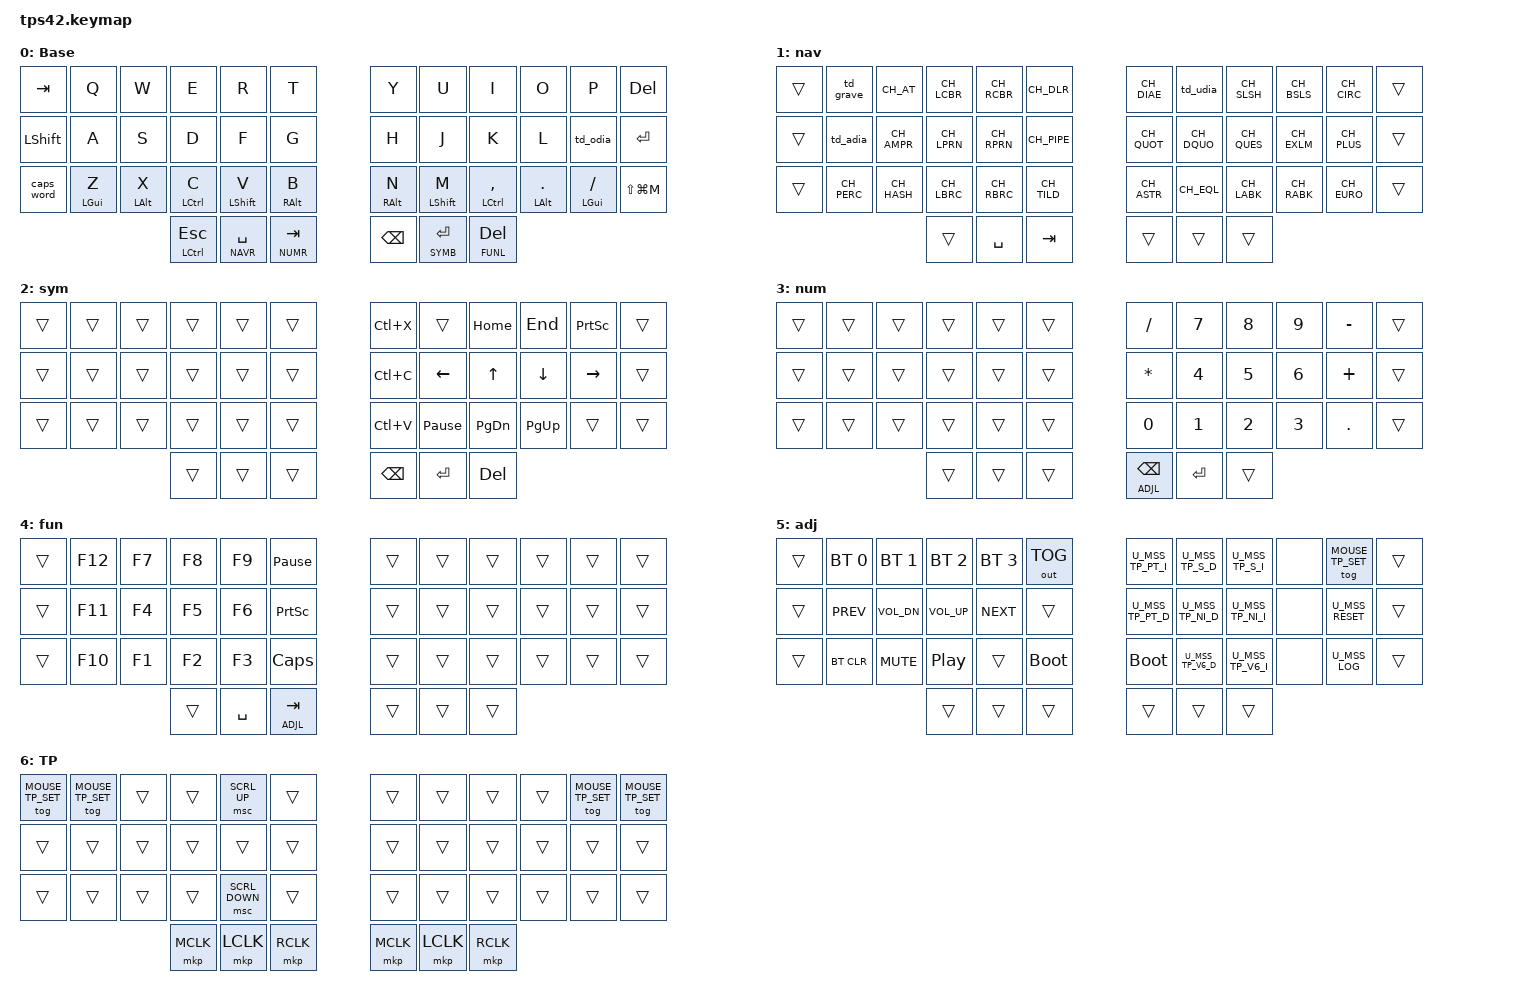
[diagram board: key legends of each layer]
/*
 * Copyright (c) 2020 The ZMK Contributors
 *
 * SPDX-License-Identifier: MIT
 */

#include <behaviors.dtsi>
#include <dt-bindings/zmk/keys.h>
#include <dt-bindings/zmk/ext_power.h>
#include <dt-bindings/zmk/outputs.h>
#include <dt-bindings/zmk/bt.h>

#include "include/swiss-keymap.h"

#define BASE           0
#define NAVR           1
#define SYMB           2
#define NUMR           3
#define FUNL           4
#define ADJL           5    
#define MOUSE_TP_SET   6
#define MOUSE_TP       7



/*
 * Defines to enable/disable features
 *
 * These defines allow us to conditionally enable and disable parts of the keymap config.
 *
 * For example, if we decide to build the firmware without the mouse features, we can
 * disable all the config options that rely on those forks and modules without having
 * to edit the entire keymap file manually every time.
 */
#define HAS_MOUSE_TP

#ifdef HAS_MOUSE_KEYS
  #include <dt-bindings/zmk/mouse.h>
  #include <behaviors/mouse_keys.dtsi>
#endif  // HAS_MOUSE_KEYS

#ifdef HAS_MOUSE_TP
  // We store the trackpoint settings in a separate file
  // to make organization a little easier.
  #include "include/mouse_tp.dtsi"
#endif  // HAS_MOUSE_TP



// Adjust layer keys based on enabled features.
//
// This prevents build errors when we build the firmware
// without the mouse keys PR or the TP module.

#ifdef HAS_MOUSE_TP
  #define U_TOG_TP_SET &tog MOUSE_TP_SET
#else
  #define U_TOG_TP_SET &none
#endif  // HAS_MOUSE_TP

// Disable line-wrap in your editor to see a "visualization" of the key layouts
/ {
    macros {
        md_code_i: md_code_i {
            label = "MD Code Inline";
            compatible = "zmk,behavior-macro";
            #binding-cells = <0>;
            bindings
                = <&macro_tap_time 50>
                , <&macro_tap &kp CH_GRV>
                , <&macro_tap_time 10>
                , <&macro_tap &kp CH_GRV &kp LEFT>
                ;
        };
        md_code_b: md_code_b {
            label = "MD Code Block";
            compatible = "zmk,behavior-macro";
            #binding-cells = <0>;
            bindings
                = <&macro_tap_time 10>
                , <&macro_tap &kp CH_GRV &kp CH_GRV &kp CH_GRV &kp CH_GRV &kp CH_GRV &kp CH_GRV &kp LEFT &kp LEFT &kp LEFT &kp RET &kp RET &kp UP>
                ;
        };
        up_ch_adia: up_ch_adia {
            label = "Uppercase CH_ADIA";
            compatible = "zmk,behavior-macro";
            #binding-cells = <0>;
            bindings
                = <&macro_tap_time 10>
                , <&macro_tap &kp CLCK &kp CH_ADIA &kp CLCK>
                ;
        };
        up_ch_udia: up_ch_udia {
            label = "Uppercase CH_UDIA";
            compatible = "zmk,behavior-macro";
            #binding-cells = <0>;
            bindings
                = <&macro_tap_time 10>
                , <&macro_tap &kp CLCK &kp CH_UDIA &kp CLCK>
                ;
        };
        
        up_ch_odia: up_ch_odia {
            label = "Uppercase CH_ODIA";
            compatible = "zmk,behavior-macro";
            #binding-cells = <0>;
            bindings
                = <&macro_tap_time 10>
                , <&macro_tap &kp CLCK &kp CH_ODIA &kp CLCK>
                ;
        };
    };
	behaviors {
        hm: homerow_mods {
            compatible = "zmk,behavior-hold-tap";
            label = "HOMEROW_MODS";
            #binding-cells = <2>;
            tapping-term-ms = <180>;
            quick_tap_ms = <0>;
            flavor = "tap-preferred";
            bindings = <&kp>, <&kp>;
        };
         td_udia: tap_dance_udia {
            compatible = "zmk,behavior-tap-dance";
            label = "TAP_DANCE_UDIA";
            #binding-cells = <0>;
            tapping-term-ms = <200>;
            bindings = <&kp CH_UDIA>, <&up_ch_udia>;
        };
         td_adia: tap_dance_adia {
            compatible = "zmk,behavior-tap-dance";
            label = "TAP_DANCE_ADIA";
            #binding-cells = <0>;
            tapping-term-ms = <200>;
            bindings = <&kp CH_ADIA>, <&up_ch_adia>;
        };
         td_odia: tap_dance_odia {
            compatible = "zmk,behavior-tap-dance";
            label = "TAP_DANCE_ODIA";
            #binding-cells = <0>;
            tapping-term-ms = <200>;
            bindings = <&kp CH_ODIA>, <&up_ch_odia>;
        };
        td_grave: tap_dance_grave {
            compatible = "zmk,behavior-tap-dance";
            label = "TAP_DANCE_GRAVE";
            #binding-cells = <0>;
            tapping-term-ms = <300>;
            bindings = <&kp CH_GRV>, <&md_code_i>, <&md_code_b>;
        };
    };
// /*
//  *
//  *          ,-----------------------------.                                ,-----------------------------.
//  *          | 00 | 01 | 02 | 03 | 04 | 05 |                                | 06 | 07 | 08 | 09 | 10 | 11 |
//  *          ,----+----+----+----+----+----|                                |----+----+----+----+----+----.
//  *          | 12 | 13 | 14 | 15 | 16 | 17 |                                | 18 | 19 | 20 | 21 | 22 | 23 |
//  *          |----+----+----+----+----+----|                                |----+----+----+----+----+----|
//  *          | 24 | 25 | 26 | 27 | 28 | 29 |                                | 30 | 31 | 32 | 33 | 34 | 35 |
//  *          `-------------------+----+----+----.                      ,----+----+----+-------------------'
//  *                              | 36 | 37 | 38 |                      | 39 | 40 | 41 |
//  *                              `--------------'                      `--------------'
//  */

    combos {
        compatible = "zmk,combos";
        combo_caps_word {
            timeout-ms = <50>;
            key-positions = <28 31>;
            bindings = <&caps_word>;
        };
    };
    keymap {
    compatible = "zmk,keymap";

    Base_layer {
      display-name = "Base";
      bindings = <
// ╭────────────────────────┬────────────────────────┬────────────────────────┬────────────────────────┬────────────────────────┬────────────────────────╮    ╭────────────────────────┬────────────────────────┬────────────────────────┬───────────────────────┬────────────────────────┬────────────────────────╮
     &kp TAB                  &kp Q                    &kp W                    &kp E                    &kp R                    &kp T                         &kp Y                    &kp U                    &kp I                    &kp O                    &kp P                    &kp DEL
// ├────────────────────────┼────────────────────────┼────────────────────────┼────────────────────────┼────────────────────────┼────────────────────────┤    ├────────────────────────┼────────────────────────┼────────────────────────┼───────────────────────┼────────────────────────┼────────────────────────┤
     &kp LSHIFT               &kp A                    &kp S                    &kp D                    &kp F                    &kp G                         &kp H                    &kp J                    &kp K                    &kp L                    &td_odia                 &kp ENTER
// ├────────────────────────┼────────────────────────┼────────────────────────┼────────────────────────┼────────────────────────┼────────────────────────┤    ├────────────────────────┼────────────────────────┼────────────────────────┼───────────────────────┼────────────────────────┼────────────────────────┤
     &caps_word               &hm LGUI Z               &hm LALT X               &hm LCTRL C              &hm LSHFT V              &hm RALT B                    &hm RALT N               &hm LSHFT M              &hm LCTRL COMMA          &hm LALT DOT             &hm LGUI FSLH            &kp LS(LG(M))
// ╰────────────────────────┴────────────────────────┴────────────────────────┴────────────────────────┼────────────────────────┼────────────────────────┤    ├────────────────────────┼────────────────────────┼────────────────────────┼───────────────────────┼────────────────────────┼────────────────────────╯
                                                                                &mt LCTRL ESC            &lt NAVR SPACE           &lt NUMR TAB                  &kp BSPC                 &lt SYMB RET             &lt FUNL DEL 
//                                                                            ╰────────────────────────┴────────────────────────┴────────────────────────╯    ╰────────────────────────┴────────────────────────┴────────────────────────╯
      >;
    };


    Navigation_layer {
      display-name = "nav";
      bindings = <
// ╭────────────────────────┬────────────────────────┬────────────────────────┬────────────────────────┬────────────────────────┬────────────────────────╮    ╭────────────────────────┬────────────────────────┬────────────────────────┬────────────────────────┬────────────────────────┬────────────────────────╮
     &trans                   &td_grave                &kp CH_AT                &kp CH_LCBR              &kp CH_RCBR              &kp CH_DLR                    &kp CH_DIAE              &td_udia                 &kp CH_SLSH              &kp CH_BSLS              &kp CH_CIRC              &trans
// ├────────────────────────┼────────────────────────┼────────────────────────┼────────────────────────┼────────────────────────┼────────────────────────┤    ├────────────────────────┼────────────────────────┼────────────────────────┼────────────────────────┼────────────────────────┼────────────────────────┤
     &trans                   &td_adia                 &kp CH_AMPR              &kp CH_LPRN              &kp CH_RPRN              &kp CH_PIPE                   &kp CH_QUOT              &kp CH_DQUO              &kp CH_QUES              &kp CH_EXLM              &kp CH_PLUS              &trans
// ├────────────────────────┼────────────────────────┼────────────────────────┼────────────────────────┼────────────────────────┼────────────────────────┤    ├────────────────────────┼────────────────────────┼────────────────────────┼────────────────────────┼────────────────────────┼────────────────────────┤
     &trans                   &kp CH_PERC              &kp CH_HASH              &kp CH_LBRC              &kp CH_RBRC              &kp CH_TILD                   &kp CH_ASTR              &kp CH_EQL               &kp CH_LABK              &kp CH_RABK              &kp CH_EURO              &trans
// ╰────────────────────────┴────────────────────────┴────────────────────────┴────────────────────────┼────────────────────────┼────────────────────────┤    ├────────────────────────┼────────────────────────┼────────────────────────┼────────────────────────┴────────────────────────┼────────────────────────╯
                                                                                &trans                   &kp SPACE                &kp TAB                       &trans                   &trans                   &trans
//                                                                            ╰────────────────────────┴────────────────────────┴────────────────────────╯    ╰────────────────────────┴────────────────────────┴────────────────────────╯
      >;
    };


    Symbol_layer {
      display-name = "sym";
      bindings = <
// ╭────────────────────────┬────────────────────────┬────────────────────────┬────────────────────────┬────────────────────────┬────────────────────────╮    ╭────────────────────────┬────────────────────────┬────────────────────────┬────────────────────────┬────────────────────────┬────────────────────────╮
     &trans                   &trans                   &trans                   &trans                   &trans                   &trans                        &kp LC(X)                &trans                   &kp HOME                 &kp END                  &kp PSCRN                 &trans
// ├────────────────────────┼────────────────────────┼────────────────────────┼────────────────────────┼────────────────────────┼────────────────────────┤    ├────────────────────────┼────────────────────────┼────────────────────────┼────────────────────────┼────────────────────────┼────────────────────────┤
     &trans                   &trans                   &trans                   &trans                   &trans                   &trans                        &kp LC(C)                &kp LEFT                 &kp UP                   &kp DOWN                 &kp RIGHT                 &trans
// ├────────────────────────┼────────────────────────┼────────────────────────┼────────────────────────┼────────────────────────┼────────────────────────┤    ├────────────────────────┼────────────────────────┼────────────────────────┼────────────────────────┼────────────────────────┼────────────────────────┤
     &trans                   &trans                   &trans                   &trans                   &trans                   &trans                        &kp LC(V)                &kp PAUSE_BREAK          &kp PG_DN                &kp PG_UP                &trans                    &trans
// ╰────────────────────────┴────────────────────────┴────────────────────────┴────────────────────────┼────────────────────────┼────────────────────────┤    ├────────────────────────┼────────────────────────┼────────────────────────┼────────────────────────┴────────────────────────┼────────────────────────╯
                                                                                &trans                   &trans                   &trans                        &kp BSPC                 &kp RET                  &kp DEL
//                                                                            ╰────────────────────────┴────────────────────────┴────────────────────────╯    ╰────────────────────────┴────────────────────────┴────────────────────────╯
      >;
    };


    Number_layer {
      display-name = "num";
      bindings = <
// ╭────────────────────────┬────────────────────────┬────────────────────────┬────────────────────────┬────────────────────────┬────────────────────────╮    ╭────────────────────────┬────────────────────────┬────────────────────────┬────────────────────────┬────────────────────────┬────────────────────────╮
     &trans                   &trans                   &trans                   &trans                   &trans                   &trans                        &kp SLASH                &kp N7                   &kp N8                   &kp N9                   &kp MINUS                &trans
// ├────────────────────────┼────────────────────────┼────────────────────────┼────────────────────────┼────────────────────────┼────────────────────────┤    ├────────────────────────┼────────────────────────┼────────────────────────┼────────────────────────┼────────────────────────┼────────────────────────┤
     &trans                   &trans                   &trans                   &trans                   &trans                   &trans                        &kp ASTRK                &kp N4                   &kp N5                   &kp N6                   &kp PLUS                 &trans
// ├────────────────────────┼────────────────────────┼────────────────────────┼────────────────────────┼────────────────────────┼────────────────────────┤    ├────────────────────────┼────────────────────────┼────────────────────────┼────────────────────────┼────────────────────────┼────────────────────────┤
     &trans                   &trans                   &trans                   &trans                   &trans                   &trans                        &kp N0                   &kp N1                   &kp N2                   &kp N3                   &kp DOT                  &trans
// ╰────────────────────────┴────────────────────────┴────────────────────────┴────────────────────────┼────────────────────────┼────────────────────────┤    ├────────────────────────┼────────────────────────┼────────────────────────┼────────────────────────┴────────────────────────┼────────────────────────╯
                                                                                &trans                   &trans                   &trans                        &lt ADJL BSPC            &kp RET                  &trans
//                                                                            ╰────────────────────────┴────────────────────────┴────────────────────────╯    ╰────────────────────────┴────────────────────────┴────────────────────────╯
      >;
    };


    Function_layer {
      display-name = "fun";
      bindings = <
// ╭────────────────────────┬────────────────────────┬────────────────────────┬────────────────────────┬────────────────────────┬────────────────────────╮    ╭────────────────────────┬────────────────────────┬────────────────────────┬────────────────────────┬────────────────────────┬────────────────────────╮
     &trans                   &kp F12                  &kp F7                   &kp F8                   &kp F9                   &kp PAUSE_BREAK               &trans                   &trans                   &trans                   &trans                   &trans                   &trans
// ├────────────────────────┼────────────────────────┼────────────────────────┼────────────────────────┼────────────────────────┼────────────────────────┤    ├────────────────────────┼────────────────────────┼────────────────────────┼────────────────────────┼────────────────────────┼────────────────────────┤
     &trans                   &kp F11                  &kp F4                   &kp F5                   &kp F6                   &kp PSCRN                     &trans                   &trans                   &trans                   &trans                   &trans                   &trans
// ├────────────────────────┼────────────────────────┼────────────────────────┼────────────────────────┼────────────────────────┼────────────────────────┤    ├────────────────────────┼────────────────────────┼────────────────────────┼────────────────────────┼────────────────────────┼────────────────────────┤
     &trans                   &kp F10                  &kp F1                   &kp F2                   &kp F3                   &kp CLCK                      &trans                   &trans                   &trans                   &trans                   &trans                   &trans
// ╰────────────────────────┴────────────────────────┴────────────────────────┴────────────────────────┼────────────────────────┼────────────────────────┤    ├────────────────────────┼────────────────────────┼────────────────────────┼────────────────────────┴────────────────────────┼────────────────────────╯
                                                                                &trans                   &kp SPACE                &lt ADJL TAB                  &trans                   &trans                   &trans
//                                                                            ╰────────────────────────┴────────────────────────┴────────────────────────╯    ╰────────────────────────┴────────────────────────┴────────────────────────╯
      >;
    };

#ifndef HAS_MOUSE_TP

    Adjustment_layer {
      display-name = "adj";
      bindings = <
// ╭────────────────────────┬────────────────────────┬────────────────────────┬────────────────────────┬────────────────────────┬────────────────────────╮    ╭────────────────────────┬────────────────────────┬────────────────────────┬────────────────────────┬────────────────────────┬────────────────────────╮
     &trans                   &bt BT_SEL 0             &bt BT_SEL 1             &bt BT_SEL 2             &bt BT_SEL 3             &out OUT_TOG                  &trans                   &trans                   &trans                   &trans                   &trans                   &trans
// ├────────────────────────┼────────────────────────┼────────────────────────┼────────────────────────┼────────────────────────┼────────────────────────┤    ├────────────────────────┼────────────────────────┼────────────────────────┼────────────────────────┼────────────────────────┼────────────────────────┤
     &trans                   &kp C_PREV               &kp C_VOL_DN             &kp C_VOL_UP             &kp C_NEXT               &trans                        &trans                   &trans                   &trans                   &trans                   &trans                   &trans
// ├────────────────────────┼────────────────────────┼────────────────────────┼────────────────────────┼────────────────────────┼────────────────────────┤    ├────────────────────────┼────────────────────────┼────────────────────────┼────────────────────────┼────────────────────────┼────────────────────────┤
     &trans                   &bt BT_CLR               &kp K_MUTE               &kp C_PP                 &trans                   &bootloader                   &bootloader              &trans                   &trans                   &trans                   &trans                   &trans
// ╰────────────────────────┴────────────────────────┴────────────────────────┴────────────────────────┼────────────────────────┼────────────────────────┤    ├────────────────────────┼────────────────────────┼────────────────────────┼────────────────────────┴────────────────────────┼────────────────────────╯
                                                                                &trans                   &trans                   &trans                        &trans                   &trans                   &trans
//                                                                            ╰────────────────────────┴────────────────────────┴────────────────────────╯    ╰────────────────────────┴────────────────────────┴────────────────────────╯
      >;
    };

#endif
#ifdef HAS_MOUSE_TP

    // You can find the defines for the actual key press behaviors in `include/mouse_tp.dtsi`.

    Adjustment_layer {
      display-name = "adj";
      bindings = <
// ╭────────────────────────┬────────────────────────┬────────────────────────┬────────────────────────┬────────────────────────┬────────────────────────╮    ╭────────────────────────┬────────────────────────┬────────────────────────┬────────────────────────┬────────────────────────┬────────────────────────╮
     &trans                   &bt BT_SEL 0             &bt BT_SEL 1             &bt BT_SEL 2             &bt BT_SEL 3             &out OUT_TOG                  U_MSS_TP_PT_I            U_MSS_TP_S_D             U_MSS_TP_S_I             &none                    U_TOG_TP_SET             &trans
// ├────────────────────────┼────────────────────────┼────────────────────────┼────────────────────────┼────────────────────────┼────────────────────────┤    ├────────────────────────┼────────────────────────┼────────────────────────┼────────────────────────┼────────────────────────┼────────────────────────┤
     &trans                   &kp C_PREV               &kp C_VOL_DN             &kp C_VOL_UP             &kp C_NEXT               &trans                        U_MSS_TP_PT_D            U_MSS_TP_NI_D            U_MSS_TP_NI_I            &none                    U_MSS_RESET              &trans
// ├────────────────────────┼────────────────────────┼────────────────────────┼────────────────────────┼────────────────────────┼────────────────────────┤    ├────────────────────────┼────────────────────────┼────────────────────────┼────────────────────────┼────────────────────────┼────────────────────────┤
     &trans                   &bt BT_CLR               &kp K_MUTE               &kp C_PP                 &trans                   &bootloader                   &bootloader              U_MSS_TP_V6_D            U_MSS_TP_V6_I            &none                    U_MSS_LOG                &trans
// ╰────────────────────────┴────────────────────────┴────────────────────────┴────────────────────────┼────────────────────────┼────────────────────────┤    ├────────────────────────┼────────────────────────┼────────────────────────┼────────────────────────┴────────────────────────┼────────────────────────╯
                                                                                &trans                   &trans                   &trans                        &trans                   &trans                   &trans
//                                                                            ╰────────────────────────┴────────────────────────┴────────────────────────╯    ╰────────────────────────┴────────────────────────┴────────────────────────╯
      >;
    };

    // Automatically activated when the mouse or trackpoint moves.
    // Configured in `include/mouse_tp.dtsi`.
    MouseTP_layer {
      display-name = "TP";
      bindings = <
// ╭────────────────────────┬────────────────────────┬────────────────────────┬────────────────────────┬────────────────────────┬────────────────────────╮    ╭────────────────────────┬────────────────────────┬────────────────────────┬────────────────────────┬────────────────────────┬────────────────────────╮
     U_TOG_TP_SET             U_TOG_TP_SET             &trans                   &trans                   &msc SCRL_UP             &trans                        &trans                   &trans                   &trans                   &trans                   U_TOG_TP_SET              U_TOG_TP_SET
// ├────────────────────────┼────────────────────────┼────────────────────────┼────────────────────────┼────────────────────────┼────────────────────────┤    ├────────────────────────┼────────────────────────┼────────────────────────┼────────────────────────┼────────────────────────┼────────────────────────┤
     &trans                   &trans                   &trans                   &trans                   &trans                   &trans                        &trans                   &trans                   &trans                   &trans                   &trans                    &trans
// ├────────────────────────┼────────────────────────┼────────────────────────┼────────────────────────┼────────────────────────┼────────────────────────┤    ├────────────────────────┼────────────────────────┼────────────────────────┼────────────────────────┼────────────────────────┼────────────────────────┤
     &trans                   &trans                   &trans                   &trans                   &msc SCRL_DOWN           &trans                        &trans                   &trans                   &trans                   &trans                   &trans                    &trans
// ╰────────────────────────┴────────────────────────┴────────────────────────┴────────────────────────┼────────────────────────┼────────────────────────┤    ├────────────────────────┼────────────────────────┼────────────────────────┼────────────────────────┴────────────────────────┼────────────────────────╯
                                                                                &mkp MCLK                &mkp LCLK                &mkp RCLK                     &mkp MCLK                &mkp LCLK                &mkp RCLK
//                                                                            ╰────────────────────────┴────────────────────────┴────────────────────────╯    ╰────────────────────────┴────────────────────────┴────────────────────────╯
      >;
    };

#endif
  };
};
